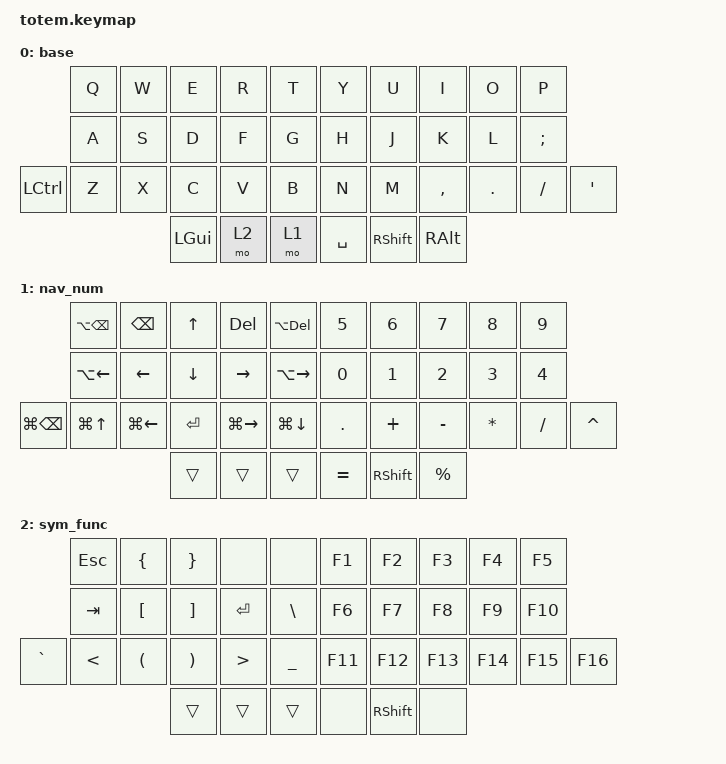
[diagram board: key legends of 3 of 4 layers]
//
//                                                        ▀▀▀▀▀     ▀▀▀▀▀          ▀▀█▀▀
//                                                        ▄▀▀▀▄  ▄  ▄▀▀▀▄  ▄  ▄▀▀▀▄  █  ▄▀▀▀▄
//                                                        █   █  █  █   █  █  █   █  █  █   █
//                                                         ▀▀▀   █   ▀▀▀   █   ▀▀▀   ▀   ▀▀▀
//                                                               █      ▄▄▄█▄▄▄    █   █  
//                                                               ▀      █  █  █     █▄█
//                                                             ▀▀▀▀▀    █  █  █      ▀
//                                                                      ▀  ▀  ▀
//
// ▄▄▄▄▄▄▄▄▄▄▄▄▄▄▄▄▄▄▄▄▄▄▄▄▄▄▄▄▄▄▄▄▄▄▄▄▄▄▄▄▄▄▄▄▄▄▄▄▄▄▄▄▄▄▄▄▄▄▄▄▄▄▄▄▄▄▄▄▄▄▄▄▄▄▄▄▄▄▄▄▄▄▄▄▄▄▄▄▄▄▄▄▄▄▄▄▄▄▄▄▄▄▄▄▄▄▄▄▄▄▄▄▄▄▄▄▄▄▄▄▄▄▄▄▄▄▄▄▄▄▄▄▄▄▄▄▄▄▄▄▄▄▄▄▄▄▄▄▄

#include <input/processors.dtsi>
#include <zephyr/dt-bindings/input/input-event-codes.h>
#include <behaviors.dtsi>
#include <dt-bindings/zmk/bt.h>
#include <dt-bindings/zmk/keys.h>
#include <dt-bindings/zmk/pointing.h>

#define ZMK_POINTING_DEFAULT_MOVE_VAL 600 // 600
#define ZMK_POINTING_DEFAULT_SCRL_VAL 20  // 10
#define base 0
#define nav_num 1
#define sym_func 2
#define device 3

// Based on @caksoylar's config, defaults in comments

&mmv {
    acceleration-exponent = <1>;          // 1
    time-to-max-speed-ms = <500>;         // 300
    delay-ms = <0>;                       // 0
};

&msc {
    acceleration-exponent = <0>;          // 0
    time-to-max-speed-ms = <300>;         // 300
    delay-ms = <0>;                       // 0
};

&mmv_input_listener {
    warp {
        layers = <nav_num>;
        input-processors = <&zip_xy_scaler 3 1>;
    };

    precision {
        layers = <sym_func>;
        input-processors = <&zip_xy_scaler 1 2>;
    };
};

/ {
    zip_scroll_scaler: zip_scroll_scaler {
        compatible = "zmk,input-processor-scaler";
        #input-processor-cells = <2>;
        type = <INPUT_EV_REL>;
        codes = <INPUT_REL_WHEEL INPUT_REL_HWHEEL>;
        track-remainders;
    };
};

&msc_input_listener {
    warp {
        layers = <nav_num>;
        input-processors = <&zip_scroll_scaler 2 1>;
    };

    precision {
        layers = <sym_func>;
        input-processors = <&zip_scroll_scaler 1 2>;
    };
};

#define U_MS_U &mmv MOVE_UP
#define U_MS_D &mmv MOVE_DOWN
#define U_MS_L &mmv MOVE_LEFT
#define U_MS_R &mmv MOVE_RIGHT
#define U_WH_U &msc SCRL_UP
#define U_WH_D &msc SCRL_DOWN
#define U_WH_L &msc SCRL_LEFT
#define U_WH_R &msc SCRL_RIGHT

/ {
    keymap {
        compatible = "zmk,keymap";

        base {
            bindings = <
           &kp Q  &kp W  &kp E     &kp R  &kp T    &kp Y      &kp U            &kp I          &kp O    &kp P
           &kp A  &kp S  &kp D     &kp F  &kp G    &kp H      &kp J            &kp K          &kp L    &kp SEMI
&kp LCTRL  &kp Z  &kp X  &kp C     &kp V  &kp B    &kp N      &kp M            &kp COMMA      &kp DOT  &kp FSLH  &kp APOS
                         &kp LGUI  &mo 2  &mo 1    &kp SPACE  &kp RIGHT_SHIFT  &kp RIGHT_ALT
            >;
        };

        nav_num {
            bindings = <
                   &kp LA(BACKSPACE)   &kp BACKSPACE  &kp UP     &kp DELETE     &kp LA(DELETE)        &kp N5      &kp N6           &kp N7       &kp N8    &kp N9
                   &kp LA(LEFT_ARROW)  &kp LEFT       &kp DOWN   &kp RIGHT      &kp LA(RIGHT)         &kp N0      &kp N1           &kp N2       &kp N3    &kp N4
&kp LG(BACKSPACE)  &kp LG(UP_ARROW)    &kp LG(LEFT)   &kp ENTER  &kp LG(RIGHT)  &kp LG(DOWN_ARROW)    &kp PERIOD  &kp PLUS         &kp MINUS    &kp STAR  &kp FSLH  &kp CARET
                                                      &trans     &trans         &trans                &kp EQUAL   &kp RIGHT_SHIFT  &kp PERCENT
            >;
        };

        sym_func {
            bindings = <
           &kp ESC        &kp LEFT_BRACE        &kp RIGHT_BRACE        &none             &none             &kp F1   &kp F2           &kp F3   &kp F4   &kp F5
           &kp TAB        &kp LBKT              &kp RBKT               &kp ENTER         &kp BSLH          &kp F6   &kp F7           &kp F8   &kp F9   &kp F10
&kp GRAVE  &kp LESS_THAN  &kp LEFT_PARENTHESIS  &kp RIGHT_PARENTHESIS  &kp GREATER_THAN  &kp UNDERSCORE    &kp F11  &kp F12          &kp F13  &kp F14  &kp F15  &kp F16
                                                &trans                 &trans            &trans            &none    &kp RIGHT_SHIFT  &none
            >;
        };

        device {
            bindings = <
       &none       &kp C_BRIGHTNESS_DEC  &kp C_BRIGHTNESS_INC  &none                                         &none    &bt BT_SEL 0    &bt BT_SEL 1    &bt BT_SEL 2  &bt BT_SEL 3     &bt BT_SEL 4
       &kp K_MUTE  &kp C_VOLUME_DOWN     &kp C_VOLUME_UP       &kp C_PLAY_PAUSE U_MS_L U_MS_D U_MS_U U_MS_R  &none    &mmv MOVE_LEFT  &mmv MOVE_DOWN  &mmv MOVE_UP  &mmv MOVE_RIGHT  &none
&none  &none       &none                 &none                 &none                                         &none    &bt BT_CLR      &none           &none         &none            &none         &none
                                         &none
            >;
        };
    };

    conditional_layers {
        compatible = "zmk,conditional-layers";

        device {
            if-layers = <1 2>;
            then-layer = <3>;
        };
    };
};
